# STM32G0B0 register map
File version: 1.0
CPU: CM0 r0p1, little endian, MPU, no FPU, 4 interrupt priority bits
Registers are 32-bit, read-write, reset 0x0 unless marked. A register's access mark holds for its fields unless they carry their own. Offsets are from the block's base; [hi:lo] are bit positions; 'fields as' and 'values as' point back to an identical list.

## USART1 (part 2 of 2) — Universal synchronous asynchronous receiver transmitter
Base 0x40013800
Same registers: USART2 0x40004400, USART3 0x40004800, USART4 0x40004C00
0x0C BRR — Baud rate register
  [15:0] BRR — USART baud rate
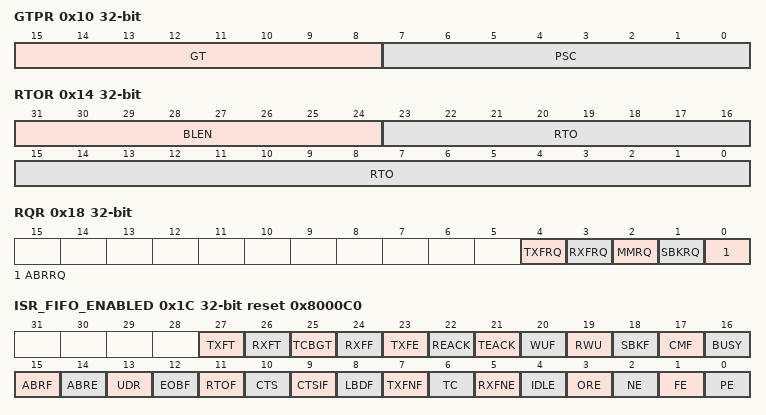
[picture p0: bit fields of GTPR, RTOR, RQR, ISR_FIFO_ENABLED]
0x10 GTPR — Guard time and prescaler register
  [15:8] GT — Guard time value This bitfield is used to program the Guard time value in terms of number of baud clock periods. This is used in Smartcard mode. The Transmission Complete flag is set after this guard time value. This bitfield can only be written when the USART is disabled (UEÂ =Â 0). Note: If Smartcard mode is not supported, this bit is reserved and must be kept at reset value. Refer to .
  [7:0] PSC — Prescaler value In IrDA low-power and normal IrDA mode: PSC[7:0] = IrDA Normal and Low-Power baud rate PSC[7:0] is used to program the prescaler for dividing the USART source clock to achieve the low-power frequency: the source clock is divided by the value given in the register (8 significant bits): In Smartcard mode: PSC[4:0]Â =Â Prescaler value PSC[4:0] is used to program the prescaler for dividing the USART source clock to provide the Smartcard clock. The value given in the register (5 significant bits) is multiplied by 2 to give the division factor of the source clock frequency: ... 0010Â 0000: Divides the source clock by 32 (IrDA mode) ... 1111Â 1111: Divides the source clock by 255 (IrDA mode) This bitfield can only be written when the USART is disabled (UEÂ =Â 0). Note: Bits [7:5] must be kept cleared if Smartcard mode is used. This bitfield is reserved and forced by hardware to '0â when the Smartcard and IrDA modes are not supported. Refer to .
    0=Reserved - do not program this value; 1=Divides the source clock by 1 (IrDA mode) / by 2 (Smarcard mode); 2=Divides the source clock by 2 (IrDA mode) / by 4 (Smartcard mode); 3=Divides the source clock by 3 (IrDA mode) / by 6 (Smartcard mode); 31=Divides the source clock by 31 (IrDA mode) / by 62 (Smartcard mode)
0x14 RTOR — Receiver timeout register
  [31:24] BLEN — Block Length
  [23:0] RTO — Receiver timeout value
0x18 RQR wo — Request register
  [4] TXFRQ — Transmit data flush request When FIFO mode is disabled, writing '1â to this bit sets the TXE flag. This enables to discard the transmit data. This bit must be used only in Smartcard mode, when data have not been sent due to errors (NACK) and the FE flag is active in the USART_ISR register. If the USART does not support Smartcard mode, this bit is reserved and must be kept at reset value. When FIFO is enabled, TXFRQ bit is set to flush the whole FIFO. This sets the TXFE flag (Transmit FIFO empty, bit 23 in the USART_ISR register). Flushing the Transmit FIFO is supported in both UART and Smartcard modes. Note: In FIFO mode, the TXFNF flag is reset during the flush request until TxFIFO is empty in order to ensure that no data are written in the data register.
  [3] RXFRQ — Receive data flush request Writing 1 to this bit empties the entire receive FIFO i.e. clears the bit RXFNE. This enables to discard the received data without reading them, and avoid an overrun condition.
  [2] MMRQ — Mute mode request Writing 1 to this bit puts the USART in Mute mode and resets the RWU flag.
  [1] SBKRQ — Send break request Writing 1 to this bit sets the SBKF flag and request to send a BREAK on the line, as soon as the transmit machine is available. Note: When the application needs to send the break character following all previously inserted data, including the ones not yet transmitted, the software should wait for the TXE flag assertion before setting the SBKRQ bit.
  [0] ABRRQ — Auto baud rate request Writing 1 to this bit resets the ABRF flag in the USART_ISR and requests an automatic baud rate measurement on the next received data frame. Note: If the USART does not support the auto baud rate feature, this bit is reserved and must be kept at reset value. Refer to .
0x1C ISR_FIFO_ENABLED ro reset 0x8000C0 — Interrupt & status register
  [27] TXFT — TXFIFO threshold flag This bit is set by hardware when the TXFIFO reaches the threshold programmed in TXFTCFG of USART_CR3 register i.e. the TXFIFO contains TXFTCFG empty locations. An interrupt is generated if the TXFTIE bit Â =Â 1 (bit 31) in the USART_CR3 register.
    0=TXFIFO does not reach the programmed threshold; 1=TXFIFO reached the programmed threshold
  [26] RXFT — RXFIFO threshold flag This bit is set by hardware when the threshold programmed in RXFTCFG in USART_CR3 register is reached. This means that there are (RXFTCFG - 1) data in the Receive FIFO and one data in the USART_RDR register. An interrupt is generated if the RXFTIE bit Â =Â 1 (bit 27) in the USART_CR3 register. Note: When the RXFTCFG threshold is configured to '101â, RXFT flag is set if 16 data are available i.e. 15 data in the RXFIFO and 1 data in the USART_RDR. Consequently, the 17th received data does not cause an overrun error. The overrun error occurs after receiving the 18th data.
    0=Receive FIFO does not reach the programmed threshold; 1=Receive FIFO reached the programmed threshold
  [25] TCBGT — Transmission complete before guard time flag This bit is set when the last data written in the USART_TDR has been transmitted correctly out of the shift register. It is set by hardware in Smartcard mode, if the transmission of a frame containing data is complete and if the smartcard did not send back any NACK. An interrupt is generated if TCBGTIEÂ =Â 1 in the USART_CR3 register. This bit is cleared by software, by writing 1 to the TCBGTCF in the USART_ICR register or by a write to the USART_TDR register. Note: If the USART does not support the Smartcard mode, this bit is reserved and kept at reset value. If the USART supports the Smartcard mode and the Smartcard mode is enabled, the TCBGT reset value is '1â. Refer to on pageÂ 835.
    0=Transmission is not complete or transmission is complete unsuccessfully (i.e. a NACK is received from the card); 1=Transmission is complete successfully (before Guard time completion and there is no NACK from the smart card)
  [24] RXFF — RXFIFO full This bit is set by hardware when the number of received data corresponds to RXFIFOÂ sizeÂ +Â 1 (RXFIFO full + 1 data in the USART_RDR register. An interrupt is generated if the RXFFIE bit Â =Â 1 in the USART_CR1 register.
    0=RXFIFO not full; 1=RXFIFO Full
  [23] TXFE — TXFIFO empty This bit is set by hardware when TXFIFO is empty. When the TXFIFO contains at least one data, this flag is cleared. The TXFE flag can also be set by writing 1 to the bit TXFRQ (bit 4) in the USART_RQR register. An interrupt is generated if the TXFEIE bit Â =Â 1 (bit 30) in the USART_CR1 register.
    0=TXFIFO not empty; 1=TXFIFO empty
  [22] REACK — Receive enable acknowledge flag This bit is set/reset by hardware, when the Receive Enable value is taken into account by the USART. It can be used to verify that the USART is ready for reception before entering low-power mode. Note: If the USART does not support the wakeup from Stop feature, this bit is reserved and kept at reset value. Refer to .
  [21] TEACK — Transmit enable acknowledge flag This bit is set/reset by hardware, when the Transmit Enable value is taken into account by the USART. It can be used when an idle frame request is generated by writing TEÂ =Â 0, followed by TEÂ =Â 1 in the USART_CR1 register, in order to respect the TEÂ =Â 0 minimum period.
  [20] WUF — Wakeup from low-power mode flag This bit is set by hardware, when a wakeup event is detected. The event is defined by the WUS bitfield. It is cleared by software, writing a 1 to the WUCF in the USART_ICR register. An interrupt is generated if WUFIEÂ =Â 1 in the USART_CR3 register. Note: When UESM is cleared, WUF flag is also cleared. If the USART does not support the wakeup from Stop feature, this bit is reserved and kept at reset value. Refer to .
  [19] RWU — Receiver wakeup from Mute mode This bit indicates if the USART is in Mute mode. It is cleared/set by hardware when a wakeup/mute sequence is recognized. The Mute mode control sequence (address or IDLE) is selected by the WAKE bit in the USART_CR1 register. When wakeup on IDLE mode is selected, this bit can only be set by software, writing 1 to the MMRQ bit in the USART_RQR register. Note: If the USART does not support the wakeup from Stop feature, this bit is reserved and kept at reset value. Refer to .
    0=Receiver in active mode; 1=Receiver in Mute mode
  [18] SBKF — Send break flag This bit indicates that a send break character was requested. It is set by software, by writing 1 to the SBKRQ bit in the USART_CR3 register. It is automatically reset by hardware during the stop bit of break transmission.
    0=Break character transmitted; 1=Break character requested by setting SBKRQ bit in USART_RQR register
  [17] CMF — Character match flag This bit is set by hardware, when a the character defined by ADD[7:0] is received. It is cleared by software, writing 1 to the CMCF in the USART_ICR register. An interrupt is generated if CMIEÂ =Â 1in the USART_CR1 register.
    0=No Character match detected; 1=Character Match detected
  [16] BUSY — Busy flag This bit is set and reset by hardware. It is active when a communication is ongoing on the RX line (successful start bit detected). It is reset at the end of the reception (successful or not).
    0=USART is idle (no reception); 1=Reception on going
  [15] ABRF — Auto baud rate flag This bit is set by hardware when the automatic baud rate has been set (RXFNE is also set, generating an interrupt if RXFNEIE = 1) or when the auto baud rate operation was completed without success (ABREÂ =Â 1) (ABRE, RXFNE and FE are also set in this case) It is cleared by software, in order to request a new auto baud rate detection, by writing 1 to the ABRRQ in the USART_RQR register. Note: If the USART does not support the auto baud rate feature, this bit is reserved and kept at reset value.
  [14] ABRE — Auto baud rate error This bit is set by hardware if the baud rate measurement failed (baud rate out of range or character comparison failed) It is cleared by software, by writing 1 to the ABRRQ bit in the USART_CR3 register. Note: If the USART does not support the auto baud rate feature, this bit is reserved and kept at reset value.
  [13] UDR — SPI slave underrun error flag In slave transmission mode, this flag is set when the first clock pulse for data transmission appears while the software has not yet loaded any value into USART_TDR. This flag is reset by setting UDRCF bit in the USART_ICR register. Note: If the USART does not support the SPI slave mode, this bit is reserved and kept at reset value. Refer to .
    0=No underrun error; 1=underrun error
  [12] EOBF — End of block flag This bit is set by hardware when a complete block has been received (for example TÂ =Â 1 Smartcard mode). The detection is done when the number of received bytes (from the start of the block, including the prologue) is equal or greater than BLEN + 4. An interrupt is generated if the EOBIEÂ =Â 1 in the USART_CR2 register. It is cleared by software, writing 1 to the EOBCF in the USART_ICR register. Note: If Smartcard mode is not supported, this bit is reserved and kept at reset value. Refer to .
    0=End of Block not reached; 1=End of Block (number of characters) reached
  [11] RTOF — Receiver timeout This bit is set by hardware when the timeout value, programmed in the RTOR register has lapsed, without any communication. It is cleared by software, writing 1 to the RTOCF bit in the USART_ICR register. An interrupt is generated if RTOIEÂ =Â 1 in the USART_CR2 register. In Smartcard mode, the timeout corresponds to the CWT or BWT timings. Note: If a time equal to the value programmed in RTOR register separates 2 characters, RTOF is not set. If this time exceeds this value + 2 sample times (2/16 or 2/8, depending on the oversampling method), RTOF flag is set. The counter counts even if RE = 0 but RTOF is set only when RE = 1. If the timeout has already elapsed when RE is set, then RTOF is set. If the USART does not support the Receiver timeout feature, this bit is reserved and kept at reset value.
    0=Timeout value not reached; 1=Timeout value reached without any data reception
  [10] CTS — CTS flag This bit is set/reset by hardware. It is an inverted copy of the status of the nCTS input pin. Note: If the hardware flow control feature is not supported, this bit is reserved and kept at reset value.
    0=nCTS line set; 1=nCTS line reset
  [9] CTSIF — CTS interrupt flag This bit is set by hardware when the nCTS input toggles, if the CTSE bit is set. It is cleared by software, by writing 1 to the CTSCF bit in the USART_ICR register. An interrupt is generated if CTSIEÂ =Â 1 in the USART_CR3 register. Note: If the hardware flow control feature is not supported, this bit is reserved and kept at reset value.
    0=No change occurred on the nCTS status line; 1=A change occurred on the nCTS status line
  [8] LBDF — LIN break detection flag This bit is set by hardware when the LIN break is detected. It is cleared by software, by writing 1 to the LBDCF in the USART_ICR. An interrupt is generated if LBDIE = 1 in the USART_CR2 register. Note: If the USART does not support LIN mode, this bit is reserved and kept at reset value. Refer to .
    0=LIN Break not detected; 1=LIN break detected
  [7] TXFNF — TXFIFO not full TXFNF is set by hardware when TXFIFO is not full meaning that data can be written in the USART_TDR. Every write operation to the USART_TDR places the data in the TXFIFO. This flag remains set until the TXFIFO is full. When the TXFIFO is full, this flag is cleared indicating that data can not be written into the USART_TDR. An interrupt is generated if the TXFNFIE bit =1 in the USART_CR1 register. Note: The TXFNF is kept reset during the flush request until TXFIFO is empty. After sending the flush request (by setting TXFRQ bit), the flag TXFNF should be checked prior to writing in TXFIFO (TXFNF and TXFE are set at the same time). This bit is used during single buffer transmission.
    0=Transmit FIFO is full; 1=Transmit FIFO is not full
  [6] TC — Transmission complete This bit indicates that the last data written in the USART_TDR has been transmitted out of the shift register. It is set by hardware when the transmission of a frame containing data is complete and when TXFE is set. An interrupt is generated if TCIEÂ =Â 1 in the USART_CR1 register. TC bit is is cleared by software, by writing 1 to the TCCF in the USART_ICR register or by a write to the USART_TDR register. Note: If TE bit is reset and no transmission is on going, the TC bit is immediately set.
    0=Transmission is not complete; 1=Transmission is complete
  [5] RXFNE — RXFIFO not empty RXFNE bit is set by hardware when the RXFIFO is not empty, meaning that data can be read from the USART_RDR register. Every read operation from the USART_RDR frees a location in the RXFIFO. RXFNE is cleared when the RXFIFO is empty. The RXFNE flag can also be cleared by writing 1 to the RXFRQ in the USART_RQR register. An interrupt is generated if RXFNEIEÂ =Â 1 in the USART_CR1 register.
    0=Data is not received; 1=Received data is ready to be read
  [4] IDLE — Idle line detected This bit is set by hardware when an Idle Line is detected. An interrupt is generated if IDLEIEÂ =Â 1 in the USART_CR1 register. It is cleared by software, writing 1 to the IDLECF in the USART_ICR register. Note: The IDLE bit is not set again until the RXFNE bit has been set (i.e. a new idle line occurs). If Mute mode is enabled (MMEÂ =Â 1), IDLE is set if the USART is not mute (RWUÂ =Â 0), whatever the Mute mode selected by the WAKE bit. If RWUÂ =Â 1, IDLE is not set.
    0=No Idle line is detected; 1=Idle line is detected
  [3] ORE — Overrun error This bit is set by hardware when the data currently being received in the shift register is ready to be transferred into the USART_RDR register while RXFF = 1. It is cleared by a software, writing 1 to the ORECF, in the USART_ICR register. An interrupt is generated if RXFNEIEÂ =Â 1 or EIE = 1 in the USART_CR1 register. Note: When this bit is set, the USART_RDR register content is not lost but the shift register is overwritten. An interrupt is generated if the ORE flag is set during multi buffer communication if the EIE bit is set. This bit is permanently forced to 0 (no overrun detection) when the bit OVRDIS is set in the USART_CR3 register.
    0=No overrun error; 1=Overrun error is detected
  [2] NE — Noise detection flag This bit is set by hardware when noise is detected on a received frame. It is cleared by software, writing 1 to the NECF bit in the USART_ICR register. Note: This bit does not generate an interrupt as it appears at the same time as the RXFNE bit which itself generates an interrupt. An interrupt is generated when the NE flag is set during multi buffer communication if the EIE bit is set. When the line is noise-free, the NE flag can be disabled by programming the ONEBIT bit to 1 to increase the USART tolerance to deviations (Refer to Tolerance of the USART receiver to clock deviation on pageÂ 861). This error is associated with the character in the USART_RDR.
    0=No noise is detected; 1=Noise is detected
  [1] FE — Framing error This bit is set by hardware when a de-synchronization, excessive noise or a break character is detected. It is cleared by software, writing 1 to the FECF bit in the USART_ICR register. When transmitting data in Smartcard mode, this bit is set when the maximum number of transmit attempts is reached without success (the card NACKs the data frame). An interrupt is generated if EIEÂ =Â 1 in the USART_CR1 register. Note: This error is associated with the character in the USART_RDR.
    0=No Framing error is detected; 1=Framing error or break character is detected
  [0] PE — Parity error This bit is set by hardware when a parity error occurs in receiver mode. It is cleared by software, writing 1 to the PECF in the USART_ICR register. An interrupt is generated if PEIE = 1 in the USART_CR1 register. Note: This error is associated with the character in the USART_RDR.
    0=No parity error; 1=Parity error
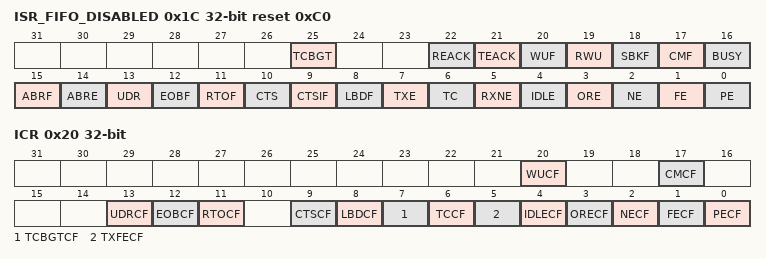
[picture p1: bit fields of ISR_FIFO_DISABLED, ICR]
0x1C ISR_FIFO_DISABLED ro reset 0xC0 (alternate view of ISR_FIFO_ENABLED) — Interrupt & status register
  [25] TCBGT — Transmission complete before guard time flag This bit is set when the last data written in the USART_TDR has been transmitted correctly out of the shift register. It is set by hardware in Smartcard mode, if the transmission of a frame containing data is complete and if the smartcard did not send back any NACK. An interrupt is generated if TCBGTIEÂ =Â 1 in the USART_CR3 register. This bit is cleared by software, by writing 1 to the TCBGTCF in the USART_ICR register or by a write to the USART_TDR register. Note: If the USART does not support the Smartcard mode, this bit is reserved and kept at reset value. If the USART supports the Smartcard mode and the Smartcard mode is enabled, the TCBGT reset value is '1â. Refer to on pageÂ 835.
    values as ISR_FIFO_ENABLED.TCBGT
  [22] REACK — Receive enable acknowledge flag This bit is set/reset by hardware, when the Receive Enable value is taken into account by the USART. It can be used to verify that the USART is ready for reception before entering low-power mode. Note: If the USART does not support the wakeup from Stop feature, this bit is reserved and kept at reset value. Refer to .
  [21] TEACK — Transmit enable acknowledge flag This bit is set/reset by hardware, when the Transmit Enable value is taken into account by the USART. It can be used when an idle frame request is generated by writing TEÂ =Â 0, followed by TEÂ =Â 1 in the USART_CR1 register, in order to respect the TEÂ =Â 0 minimum period.
  [20] WUF — Wakeup from low-power mode flag This bit is set by hardware, when a wakeup event is detected. The event is defined by the WUS bitfield. It is cleared by software, writing a 1 to the WUCF in the USART_ICR register. An interrupt is generated if WUFIEÂ =Â 1 in the USART_CR3 register. Note: When UESM is cleared, WUF flag is also cleared. If the USART does not support the wakeup from Stop feature, this bit is reserved and kept at reset value. Refer to .
  [19] RWU — Receiver wakeup from Mute mode This bit indicates if the USART is in Mute mode. It is cleared/set by hardware when a wakeup/mute sequence is recognized. The Mute mode control sequence (address or IDLE) is selected by the WAKE bit in the USART_CR1 register. When wakeup on IDLE mode is selected, this bit can only be set by software, writing 1 to the MMRQ bit in the USART_RQR register. Note: If the USART does not support the wakeup from Stop feature, this bit is reserved and kept at reset value. Refer to .
    0=Receiver in active mode; 1=Receiver in Mute mode
  [18] SBKF — Send break flag This bit indicates that a send break character was requested. It is set by software, by writing 1 to the SBKRQ bit in the USART_CR3 register. It is automatically reset by hardware during the stop bit of break transmission.
    values as ISR_FIFO_ENABLED.SBKF
  [17] CMF — Character match flag This bit is set by hardware, when a the character defined by ADD[7:0] is received. It is cleared by software, writing 1 to the CMCF in the USART_ICR register. An interrupt is generated if CMIEÂ =Â 1in the USART_CR1 register.
    0=No Character match detected; 1=Character Match detected
  [16] BUSY — Busy flag This bit is set and reset by hardware. It is active when a communication is ongoing on the RX line (successful start bit detected). It is reset at the end of the reception (successful or not).
    0=USART is idle (no reception); 1=Reception on going
  [15] ABRF — Auto baud rate flag This bit is set by hardware when the automatic baud rate has been set (RXNE is also set, generating an interrupt if RXNEIE = 1) or when the auto baud rate operation was completed without success (ABREÂ =Â 1) (ABRE, RXNE and FE are also set in this case) It is cleared by software, in order to request a new auto baud rate detection, by writing 1 to the ABRRQ in the USART_RQR register. Note: If the USART does not support the auto baud rate feature, this bit is reserved and kept at reset value.
  [14] ABRE — Auto baud rate error This bit is set by hardware if the baud rate measurement failed (baud rate out of range or character comparison failed) It is cleared by software, by writing 1 to the ABRRQ bit in the USART_CR3 register. Note: If the USART does not support the auto baud rate feature, this bit is reserved and kept at reset value.
  [13] UDR — SPI slave underrun error flag In slave transmission mode, this flag is set when the first clock pulse for data transmission appears while the software has not yet loaded any value into USART_TDR. This flag is reset by setting UDRCF bit in the USART_ICR register. Note: If the USART does not support the SPI slave mode, this bit is reserved and kept at reset value. Refer to .
    0=No underrun error; 1=underrun error
  [12] EOBF — End of block flag This bit is set by hardware when a complete block has been received (for example TÂ =Â 1 Smartcard mode). The detection is done when the number of received bytes (from the start of the block, including the prologue) is equal or greater than BLEN + 4. An interrupt is generated if the EOBIEÂ =Â 1 in the USART_CR2 register. It is cleared by software, writing 1 to the EOBCF in the USART_ICR register. Note: If Smartcard mode is not supported, this bit is reserved and kept at reset value. Refer to .
    values as ISR_FIFO_ENABLED.EOBF
  [11] RTOF — Receiver timeout This bit is set by hardware when the timeout value, programmed in the RTOR register has lapsed, without any communication. It is cleared by software, writing 1 to the RTOCF bit in the USART_ICR register. An interrupt is generated if RTOIEÂ =Â 1 in the USART_CR2 register. In Smartcard mode, the timeout corresponds to the CWT or BWT timings. Note: If a time equal to the value programmed in RTOR register separates 2 characters, RTOF is not set. If this time exceeds this value + 2 sample times (2/16 or 2/8, depending on the oversampling method), RTOF flag is set. The counter counts even if RE = 0 but RTOF is set only when RE = 1. If the timeout has already elapsed when RE is set, then RTOF is set. If the USART does not support the Receiver timeout feature, this bit is reserved and kept at reset value.
    values as ISR_FIFO_ENABLED.RTOF
  [10] CTS — CTS flag This bit is set/reset by hardware. It is an inverted copy of the status of the nCTS input pin. Note: If the hardware flow control feature is not supported, this bit is reserved and kept at reset value.
    0=nCTS line set; 1=nCTS line reset
  [9] CTSIF — CTS interrupt flag This bit is set by hardware when the nCTS input toggles, if the CTSE bit is set. It is cleared by software, by writing 1 to the CTSCF bit in the USART_ICR register. An interrupt is generated if CTSIEÂ =Â 1 in the USART_CR3 register. Note: If the hardware flow control feature is not supported, this bit is reserved and kept at reset value.
    values as ISR_FIFO_ENABLED.CTSIF
  [8] LBDF — LIN break detection flag This bit is set by hardware when the LIN break is detected. It is cleared by software, by writing 1 to the LBDCF in the USART_ICR. An interrupt is generated if LBDIE = 1 in the USART_CR2 register. Note: If the USART does not support LIN mode, this bit is reserved and kept at reset value. Refer to .
    0=LIN Break not detected; 1=LIN break detected
  [7] TXE — Transmit data register empty TXE is set by hardware when the content of the USART_TDR register has been transferred into the shift register. It is cleared by writing to the USART_TDR register. The TXE flag can also be set by writing 1 to the TXFRQ in the USART_RQR register, in order to discard the data (only in Smartcard TÂ =Â 0 mode, in case of transmission failure). An interrupt is generated if the TXEIE bit Â =Â 1 in the USART_CR1 register.
    0=Data register full; 1=Data register not full
  [6] TC — Transmission complete This bit indicates that the last data written in the USART_TDR has been transmitted out of the shift register. It is set by hardware when the transmission of a frame containing data is complete and when TXE is set. An interrupt is generated if TCIEÂ =Â 1 in the USART_CR1 register. TC bit is is cleared by software, by writing 1 to the TCCF in the USART_ICR register or by a write to the USART_TDR register. Note: If TE bit is reset and no transmission is on going, the TC bit is set immediately.
    0=Transmission is not complete; 1=Transmission is complete
  [5] RXNE — Read data register not empty RXNE bit is set by hardware when the content of the USART_RDR shift register has been transferred to the USART_RDR register. It is cleared by reading from the USART_RDR register. The RXNE flag can also be cleared by writing 1 to the RXFRQ in the USART_RQR register. An interrupt is generated if RXNEIEÂ =Â 1 in the USART_CR1 register.
    0=Data is not received; 1=Received data is ready to be read
  [4] IDLE — Idle line detected This bit is set by hardware when an Idle Line is detected. An interrupt is generated if IDLEIEÂ =Â 1 in the USART_CR1 register. It is cleared by software, writing 1 to the IDLECF in the USART_ICR register. Note: The IDLE bit is not set again until the RXNE bit has been set (i.e. a new idle line occurs). If Mute mode is enabled (MMEÂ =Â 1), IDLE is set if the USART is not mute (RWUÂ =Â 0), whatever the Mute mode selected by the WAKE bit. If RWUÂ =Â 1, IDLE is not set.
    0=No Idle line is detected; 1=Idle line is detected
  [3] ORE — Overrun error This bit is set by hardware when the data currently being received in the shift register is ready to be transferred into the USART_RDR register while RXNEÂ =Â 1. It is cleared by a software, writing 1 to the ORECF, in the USART_ICR register. An interrupt is generated if RXNEIEÂ =Â 1 or EIE Â =Â 1 in the USART_CR1 register. Note: When this bit is set, the USART_RDR register content is not lost but the shift register is overwritten. An interrupt is generated if the ORE flag is set during multi buffer communication if the EIE bit is set. This bit is permanently forced to 0 (no overrun detection) when the bit OVRDIS is set in the USART_CR3 register.
    0=No overrun error; 1=Overrun error is detected
  [2] NE — Noise detection flag This bit is set by hardware when noise is detected on a received frame. It is cleared by software, writing 1 to the NECF bit in the USART_ICR register. Note: This bit does not generate an interrupt as it appears at the same time as the RXNE bit which itself generates an interrupt. An interrupt is generated when the NE flag is set during multi buffer communication if the EIE bit is set. When the line is noise-free, the NE flag can be disabled by programming the ONEBIT bit to 1 to increase the USART tolerance to deviations (Refer to Tolerance of the USART receiver to clock deviation on pageÂ 861).
    0=No noise is detected; 1=Noise is detected
  [1] FE — Framing error This bit is set by hardware when a de-synchronization, excessive noise or a break character is detected. It is cleared by software, writing 1 to the FECF bit in the USART_ICR register. When transmitting data in Smartcard mode, this bit is set when the maximum number of transmit attempts is reached without success (the card NACKs the data frame). An interrupt is generated if EIEÂ =Â 1 in the USART_CR1 register.
    values as ISR_FIFO_ENABLED.FE
  [0] PE — Parity error This bit is set by hardware when a parity error occurs in receiver mode. It is cleared by software, writing 1 to the PECF in the USART_ICR register. An interrupt is generated if PEIE = 1 in the USART_CR1 register.
    0=No parity error; 1=Parity error
0x20 ICR wo — Interrupt flag clear register
  [20] WUCF — Wakeup from low-power mode clear flag Writing 1 to this bit clears the WUF flag in the USART_ISR register. Note: If the USART does not support the wakeup from Stop feature, this bit is reserved and must be kept at reset value. Refer to pageÂ 835.
  [17] CMCF — Character match clear flag Writing 1 to this bit clears the CMF flag in the USART_ISR register.
  [13] UDRCF — SPI slave underrun clear flag Writing 1 to this bit clears the UDRF flag in the USART_ISR register. Note: If the USART does not support SPI slave mode, this bit is reserved and must be kept at reset value. Refer to
  [12] EOBCF — End of block clear flag Writing 1 to this bit clears the EOBF flag in the USART_ISR register. Note: If the USART does not support Smartcard mode, this bit is reserved and must be kept at reset value. Refer to .
  [11] RTOCF — Receiver timeout clear flag Writing 1 to this bit clears the RTOF flag in the USART_ISR register. Note: If the USART does not support the Receiver timeout feature, this bit is reserved and must be kept at reset value. Refer to pageÂ 835.
  [9] CTSCF — CTS clear flag Writing 1 to this bit clears the CTSIF flag in the USART_ISR register. Note: If the hardware flow control feature is not supported, this bit is reserved and must be kept at reset value. Refer to .
  [8] LBDCF — LIN break detection clear flag Writing 1 to this bit clears the LBDF flag in the USART_ISR register. Note: If LIN mode is not supported, this bit is reserved and must be kept at reset value. Refer to .
  [7] TCBGTCF — Transmission complete before Guard time clear flag Writing 1 to this bit clears the TCBGT flag in the USART_ISR register.
  [6] TCCF — Transmission complete clear flag Writing 1 to this bit clears the TC flag in the USART_ISR register.
  [5] TXFECF — TXFIFO empty clear flag Writing 1 to this bit clears the TXFE flag in the USART_ISR register.
  [4] IDLECF — Idle line detected clear flag Writing 1 to this bit clears the IDLE flag in the USART_ISR register.
  [3] ORECF — Overrun error clear flag Writing 1 to this bit clears the ORE flag in the USART_ISR register.
  [2] NECF — Noise detected clear flag Writing 1 to this bit clears the NE flag in the USART_ISR register.
  [1] FECF — Framing error clear flag Writing 1 to this bit clears the FE flag in the USART_ISR register.
  [0] PECF — Parity error clear flag Writing 1 to this bit clears the PE flag in the USART_ISR register.
0x24 RDR ro — Receive data register
  [8:0] RDR — Receive data value
0x28 TDR — Transmit data register
  [8:0] TDR — Transmit data value
0x2C PRESC — Prescaler register
  [3:0] PRESCALER — Clock prescaler The USART input clock can be divided by a prescaler factor: Remaining combinations: Reserved Note: When PRESCALER is programmed with a value different of the allowed ones, programmed prescaler value is 1011 i.e. input clock divided by 256.
    0=input clock not divided; 1=input clock divided by 2; 2=input clock divided by 4; 3=input clock divided by 6; 4=input clock divided by 8; 5=input clock divided by 10; 6=input clock divided by 12; 7=input clock divided by 16; 8=input clock divided by 32; 9=input clock divided by 64; 10=input clock divided by 128; 11=input clock divided by 256
